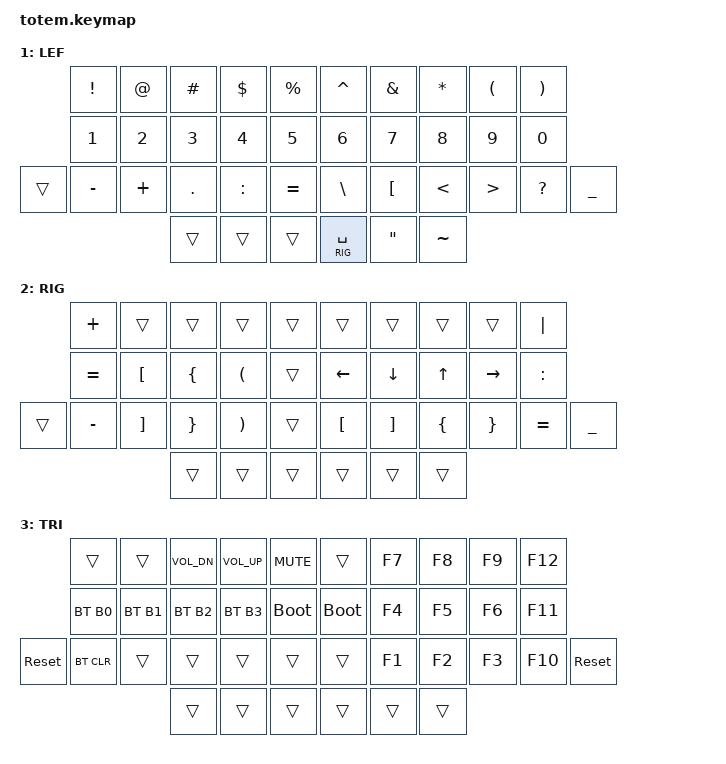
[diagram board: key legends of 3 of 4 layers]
//
//                                                        ▀▀▀▀▀     ▀▀▀▀▀          ▀▀█▀▀
//                                                        ▄▀▀▀▄  ▄  ▄▀▀▀▄  ▄  ▄▀▀▀▄  █  ▄▀▀▀▄
//                                                        █   █  █  █   █  █  █   █  █  █   █
//                                                         ▀▀▀   █   ▀▀▀   █   ▀▀▀   ▀   ▀▀▀
//                                                               █      ▄▄▄█▄▄▄    █   █
//                                                               ▀      █  █  █     █▄█
//                                                             ▀▀▀▀▀    █  █  █      ▀
//                                                                      ▀  ▀  ▀
//
// ▄▄▄▄▄▄▄▄▄▄▄▄▄▄▄▄▄▄▄▄▄▄▄▄▄▄▄▄▄▄▄▄▄▄▄▄▄▄▄▄▄▄▄▄▄▄▄▄▄▄▄▄▄▄▄▄▄▄▄▄▄▄▄▄▄▄▄▄▄▄▄▄▄▄▄▄▄▄▄▄▄▄▄▄▄▄▄▄▄▄▄▄▄▄▄▄▄▄▄▄▄▄▄▄▄▄▄▄▄▄▄▄▄▄▄▄▄▄▄▄▄▄▄▄▄▄▄▄▄▄▄▄▄▄▄▄▄▄▄▄▄▄▄▄▄▄▄▄▄

#include <behaviors.dtsi>
#include <dt-bindings/zmk/bt.h>
#include <dt-bindings/zmk/ext_power.h>
#include <dt-bindings/zmk/keys.h>

// Home row mods macro
#define HRML(k1,k2,k3,k4,k5) &ht LGUI k1  &ht LCTRL k2  &ht LALT k3  &ht LSHFT k4 &ht LG(LC(LA(LSHIFT))) k5
#define HRMR(k1,k2,k3,k4,k5) &ht LG(LC(LA(LSHIFT))) k1 &ht RSHFT k2  &ht RALT k3  &ht RCTRL k4  &ht RGUI k5

// layers
#define BAS 0
#define LEF 1
#define RIG 2
#define TRI 3

// bluetooth
#define B0    BT_SEL 0
#define B1    BT_SEL 1
#define B2    BT_SEL 2
#define B3    BT_SEL 3
#define B4    BT_SEL 4

// media
#define VOL_DN    C_VOL_DN
#define VOL_UP    C_VOL_UP
#define MUTE      C_MUTE

&mt {
    quick-tap-ms = <100>;
    global-quick-tap;
    flavor = "tap-preferred";
    tapping-term-ms = <170>;
};

&lt {
    tapping-term-ms = <240>;
    flavor = "balanced";
    quick-tap-ms = <150>;
};

/ {
    behaviors {
        ht: hold_tap {
            label = "hold_tap";
            compatible = "zmk,behavior-hold-tap";
            #binding-cells = <2>;
            flavor = "tap-preferred";
            tapping-term-ms = <175>;
            quick-tap-ms = <175>;
            require-prior-idle-ms = <125>;
            bindings = <&kp>, <&kp>;
        };
    };

    conditional_layers {
        compatible = "zmk,conditional-layers";
        tri_layer {
            if-layers = <RIG LEF>;
            then-layer = <TRI>;
        };
    };

//             ┏━━━━━━━━━━━┳━━━━━━━━━━━┳━━━━━━━━━━━┳━━━━━━━━━━━┳━━━━━━━━━━━┓   ┏━━━━━━━━━━━┳━━━━━━━━━━━┳━━━━━━━━━━━┳━━━━━━━━━━━┳━━━━━━━━━━━┓
//             ┃     0     ┃     1     ┃     2     ┃     3     ┃     4     ┃   ┃     5     ┃     6     ┃     7     ┃     8     ┃     9     ┃
//             ┣━━━━━━━━━━━╋━━━━━━━━━━━╋━━━━━━━━━━━╋━━━━━━━━━━━╋━━━━━━━━━━━┫   ┣━━━━━━━━━━━╋━━━━━━━━━━━╋━━━━━━━━━━━╋━━━━━━━━━━━╋━━━━━━━━━━━┫
//             ┃    10     ┃    11     ┃    12     ┃    13     ┃    14     ┃   ┃    15     ┃    16     ┃    17     ┃    18     ┃    19     ┃
// ┏━━━━━━━━━━━╋━━━━━━━━━━━╋━━━━━━━━━━━╋━━━━━━━━━━━╋━━━━━━━━━━━╋━━━━━━━━━━━┫   ┣━━━━━━━━━━━╋━━━━━━━━━━━╋━━━━━━━━━━━╋━━━━━━━━━━━╋━━━━━━━━━━━╋━━━━━━━━━━━┓
// ┃    20     ┃    21     ┃    22     ┃    23     ┃    24     ┃    25     ┃   ┃    26     ┃    27     ┃    28     ┃    29     ┃    30     ┃    31     ┃
// ┗━━━━━━━━━━━┻━━━━━━━━━━━┻━━━━━━━━━━━╋━━━━━━━━━━━╋━━━━━━━━━━━╋━━━━━━━━━━━┫   ┣━━━━━━━━━━━╋━━━━━━━━━━━╋━━━━━━━━━━━╋━━━━━━━━━━━┻━━━━━━━━━━━┻━━━━━━━━━━━┛
//                                     ┃    32     ┃    33     ┃    34     ┃   ┃    35     ┃    36     ┃    37     ┃
//                                     ┗━━━━━━━━━━━┻━━━━━━━━━━━┻━━━━━━━━━━━┛   ┗━━━━━━━━━━━┻━━━━━━━━━━━┻━━━━━━━━━━━┛

    combos {
        compatible = "zmk,combos";

        #define COMBO(NAME, BINDINGS, KEYPOS, LAYERS) \
        combo_##NAME { \
            bindings = <BINDINGS>; \
            key-positions = <KEYPOS>; \
            layers = <LAYERS>; \
        };

        // Brackets
        COMBO(left_bracket, &kp LBKT, 1 11, BAS LEF RIG)
        COMBO(left_paren, &kp LPAR, 2 12, BAS LEF RIG)
        COMBO(left_brace, &kp LBRC, 3 13, BAS LEF RIG)
        COMBO(right_bracket, &kp RBKT, 8 18, BAS LEF RIG)
        COMBO(right_paren, &kp RPAR, 7 17, BAS LEF RIG)
        COMBO(right_brace, &kp RBRC, 6 16, BAS LEF RIG)

        // Convenience
        COMBO(enter, &kp ENTER, 16 17 18, BAS LEF RIG)     // jkl

        // +/-
        COMBO(minus, &kp MINUS, 21 34, BAS LEF RIG)        // left wing
        COMBO(plus, &kp PLUS, 22 34, BAS LEF RIG)          // left wing
        // &/?
        COMBO(ampersand, &kp AMPS, 6 34, BAS LEF RIG)      // quick tap layer
        COMBO(layer_qmark, &kp QMARK, 30 34, BAS LEF RIG)     // quick tap layer
        COMBO(shift_qmark, &kp QMARK, 13 30, BAS LEF RIG)     // quick tap shift
    };

    keymap {
        compatible = "zmk,keymap";

// ▄▄▄▄▄▄▄▄▄▄▄▄▄▄▄▄▄▄▄▄▄▄▄▄▄▄▄▄▄▄▄▄▄▄▄▄▄▄▄▄▄▄▄▄▄▄▄▄▄▄▄▄▄▄▄▄▄▄▄▄▄▄▄▄▄▄▄▄▄▄▄▄▄▄▄▄▄▄▄▄▄▄▄▄▄▄▄▄▄▄▄▄▄▄▄▄▄▄▄▄▄▄▄▄▄▄▄▄▄▄▄▄▄▄▄▄▄▄▄▄▄▄▄▄▄▄▄▄▄▄▄▄▄▄▄▄▄▄▄▄▄▄▄▄▄▄▄▄▄

        default_layer {
            label = "BAS";
            bindings = <
//             ┏━━━━━━━━━━━┳━━━━━━━━━━━┳━━━━━━━━━━━┳━━━━━━━━━━━┳━━━━━━━━━━━┓   ┏━━━━━━━━━━━┳━━━━━━━━━━━┳━━━━━━━━━━━┳━━━━━━━━━━━┳━━━━━━━━━━━┓
//             ┃     Q     ┃     W     ┃     E     ┃     R     ┃     T     ┃   ┃     Y     ┃     U     ┃     I     ┃     O     ┃     P     ┃
//             ┣━━━━━━━━━━━╋━━━━━━━━━━━╋━━━━━━━━━━━╋━━━━━━━━━━━╋━━━━━━━━━━━┫   ┣━━━━━━━━━━━╋━━━━━━━━━━━╋━━━━━━━━━━━╋━━━━━━━━━━━╋━━━━━━━━━━━┫
//             ┃     A     ┃     S     ┃     D     ┃     F     ┃     G     ┃   ┃     H     ┃     J     ┃     K     ┃     L     ┃     ;     ┃
// ┏━━━━━━━━━━━╋━━━━━━━━━━━╋━━━━━━━━━━━╋━━━━━━━━━━━╋━━━━━━━━━━━╋━━━━━━━━━━━┫   ┣━━━━━━━━━━━╋━━━━━━━━━━━╋━━━━━━━━━━━╋━━━━━━━━━━━╋━━━━━━━━━━━╋━━━━━━━━━━━┓
// ┃ LCTRL ESC ┃     Z     ┃     X     ┃     C     ┃     V     ┃     B     ┃   ┃     N     ┃     M     ┃     ,     ┃     .     ┃     /     ┃  RSHFT =  ┃
// ┗━━━━━━━━━━━┻━━━━━━━━━━━┻━━━━━━━━━━━╋━━━━━━━━━━━╋━━━━━━━━━━━╋━━━━━━━━━━━┫   ┣━━━━━━━━━━━╋━━━━━━━━━━━╋━━━━━━━━━━━╋━━━━━━━━━━━┻━━━━━━━━━━━┻━━━━━━━━━━━┛
//                                     ┃ LSHFT TAB ┃   BSPC    ┃  LEF SPC  ┃   ┃ RIG ENTER ┃     '     ┃     `     ┃
//                                     ┗━━━━━━━━━━━┻━━━━━━━━━━━┻━━━━━━━━━━━┛   ┗━━━━━━━━━━━┻━━━━━━━━━━━┻━━━━━━━━━━━┛
// ╷           ╷           ╷           ╷           ╷           ╷           ╷   ╷           ╷           ╷           ╷           ╷           ╷           ╷

                 &kp Q       &kp W       &kp E       &kp R       &kp T           &kp Y       &kp U       &kp I       &kp O       &kp P
                HRML(A,          S,          D,          F,          G)         HRMR(H,          J,          K,          L,          SEMI)
    &mt LCTRL ESC &kp Z      &kp X       &kp C       &kp V       &kp B           &kp N       &kp M       &kp COMMA   &kp DOT     &kp FSLH    &mt RSHFT EQUAL
                                       &mt LSHFT TAB &kp BSPC    &lt LEF SPC     &lt RIG RET &kp SQT     &kp GRAVE

            >;
        };

// ▄▄▄▄▄▄▄▄▄▄▄▄▄▄▄▄▄▄▄▄▄▄▄▄▄▄▄▄▄▄▄▄▄▄▄▄▄▄▄▄▄▄▄▄▄▄▄▄▄▄▄▄▄▄▄▄▄▄▄▄▄▄▄▄▄▄▄▄▄▄▄▄▄▄▄▄▄▄▄▄▄▄▄▄▄▄▄▄▄▄▄▄▄▄▄▄▄▄▄▄▄▄▄▄▄▄▄▄▄▄▄▄▄▄▄▄▄▄▄▄▄▄▄▄▄▄▄▄▄▄▄▄▄▄▄▄▄▄▄▄▄▄▄▄▄▄▄▄▄

        left_layer {
            label = "LEF";
            bindings = <
//             ┏━━━━━━━━━━━┳━━━━━━━━━━━┳━━━━━━━━━━━┳━━━━━━━━━━━┳━━━━━━━━━━━┓   ┏━━━━━━━━━━━┳━━━━━━━━━━━┳━━━━━━━━━━━┳━━━━━━━━━━━┳━━━━━━━━━━━┓
//             ┃     !     ┃     @     ┃     #     ┃     $     ┃     %     ┃   ┃     ^     ┃     &     ┃     *     ┃     (     ┃     )     ┃
//             ┣━━━━━━━━━━━╋━━━━━━━━━━━╋━━━━━━━━━━━╋━━━━━━━━━━━╋━━━━━━━━━━━┫   ┣━━━━━━━━━━━╋━━━━━━━━━━━╋━━━━━━━━━━━╋━━━━━━━━━━━╋━━━━━━━━━━━┫
//             ┃     1     ┃     2     ┃     3     ┃     4     ┃     5     ┃   ┃     6     ┃     7     ┃     8     ┃     9     ┃     0     ┃
// ┏━━━━━━━━━━━╋━━━━━━━━━━━╋━━━━━━━━━━━╋━━━━━━━━━━━╋━━━━━━━━━━━╋━━━━━━━━━━━┫   ┣━━━━━━━━━━━╋━━━━━━━━━━━╋━━━━━━━━━━━╋━━━━━━━━━━━╋━━━━━━━━━━━╋━━━━━━━━━━━┓
// ┃    ESC    ┃     -     ┃     +     ┃     .     ┃     :     ┃     =     ┃   ┃     \     ┃     [     ┃     <     ┃     >     ┃     ?     ┃     _     ┃
// ┗━━━━━━━━━━━┻━━━━━━━━━━━┻━━━━━━━━━━━╋━━━━━━━━━━━╋━━━━━━━━━━━╋━━━━━━━━━━━┫   ┣━━━━━━━━━━━╋━━━━━━━━━━━╋━━━━━━━━━━━╋━━━━━━━━━━━┻━━━━━━━━━━━┻━━━━━━━━━━━┛
//                                     ┃ LSHFT TAB ┃   BSPC    ┃  LEF SPC  ┃   ┃  RIG SPC  ┃     "     ┃     ~     ┃
//                                     ┗━━━━━━━━━━━┻━━━━━━━━━━━┻━━━━━━━━━━━┛   ┗━━━━━━━━━━━┻━━━━━━━━━━━┻━━━━━━━━━━━┛
// ╷           ╷           ╷           ╷           ╷           ╷           ╷   ╷           ╷           ╷           ╷           ╷           ╷           ╷

                 &kp EXCL    &kp AT      &kp HASH    &kp DLLR    &kp PRCNT       &kp CARET   &kp AMPS    &kp STAR    &kp LPAR   &kp RPAR
                 &kp N1      &kp N2      &kp N3      &kp N4      &kp N5          &kp N6      &kp N7      &kp N8      &kp N9     &kp N0
    &trans       &kp MINUS   &kp PLUS    &kp PERIOD  &kp COLON   &kp EQUAL       &kp BSLH    &kp LBKT    &kp LT      &kp GT     &kp QMARK    &kp UNDER
                                         &trans      &trans      &trans          &lt RIG SPC &kp DQT     &kp TILDE

            >;
        };

// ▄▄▄▄▄▄▄▄▄▄▄▄▄▄▄▄▄▄▄▄▄▄▄▄▄▄▄▄▄▄▄▄▄▄▄▄▄▄▄▄▄▄▄▄▄▄▄▄▄▄▄▄▄▄▄▄▄▄▄▄▄▄▄▄▄▄▄▄▄▄▄▄▄▄▄▄▄▄▄▄▄▄▄▄▄▄▄▄▄▄▄▄▄▄▄▄▄▄▄▄▄▄▄▄▄▄▄▄▄▄▄▄▄▄▄▄▄▄▄▄▄▄▄▄▄▄▄▄▄▄▄▄▄▄▄▄▄▄▄▄▄▄▄▄▄▄▄▄▄

        right_layer {
            label = "RIG";
            bindings = <
//             ┏━━━━━━━━━━━┳━━━━━━━━━━━┳━━━━━━━━━━━┳━━━━━━━━━━━┳━━━━━━━━━━━┓   ┏━━━━━━━━━━━┳━━━━━━━━━━━┳━━━━━━━━━━━┳━━━━━━━━━━━┳━━━━━━━━━━━┓
//             ┃     +     ┃           ┃           ┃           ┃           ┃   ┃           ┃           ┃           ┃           ┃     |     ┃
//             ┣━━━━━━━━━━━╋━━━━━━━━━━━╋━━━━━━━━━━━╋━━━━━━━━━━━╋━━━━━━━━━━━┫   ┣━━━━━━━━━━━╋━━━━━━━━━━━╋━━━━━━━━━━━╋━━━━━━━━━━━╋━━━━━━━━━━━┫
//             ┃     =     ┃     [     ┃     {     ┃     (     ┃           ┃   ┃   LEFT    ┃   DOWN    ┃    UP     ┃   RIGHT   ┃     :     ┃
// ┏━━━━━━━━━━━╋━━━━━━━━━━━╋━━━━━━━━━━━╋━━━━━━━━━━━╋━━━━━━━━━━━╋━━━━━━━━━━━┫   ┣━━━━━━━━━━━╋━━━━━━━━━━━╋━━━━━━━━━━━╋━━━━━━━━━━━╋━━━━━━━━━━━╋━━━━━━━━━━━┓
// ┃    ESC    ┃     -     ┃     ]     ┃     }     ┃     )     ┃           ┃   ┃     [     ┃     ]     ┃     {     ┃     }     ┃     =     ┃     _     ┃
// ┗━━━━━━━━━━━┻━━━━━━━━━━━┻━━━━━━━━━━━╋━━━━━━━━━━━╋━━━━━━━━━━━╋━━━━━━━━━━━┫   ┣━━━━━━━━━━━╋━━━━━━━━━━━╋━━━━━━━━━━━╋━━━━━━━━━━━┻━━━━━━━━━━━┻━━━━━━━━━━━┛
//                                     ┃ LSHFT TAB ┃   BSPC    ┃  LEF SPC  ┃   ┃ RIG ENTER ┃     '     ┃     `     ┃
//                                     ┗━━━━━━━━━━━┻━━━━━━━━━━━┻━━━━━━━━━━━┛   ┗━━━━━━━━━━━┻━━━━━━━━━━━┻━━━━━━━━━━━┛
// ╷           ╷           ╷           ╷           ╷           ╷           ╷   ╷           ╷           ╷           ╷           ╷           ╷           ╷

                &kp PLUS    &trans      &trans      &trans       &trans         &trans      &trans      &trans      &trans      &kp PIPE
                &kp EQUAL   &kp LBKT    &kp LBRC    &kp LPAR     &trans         &kp LEFT    &kp DOWN    &kp UP      &kp RIGHT   &kp COLON
    &trans      &kp MINUS   &kp RBKT    &kp RBRC    &kp RPAR     &trans         &kp LBKT    &kp RBKT    &kp LBRC    &kp RBRC    &kp EQUAL    &kp UNDER
                                        &trans      &trans       &trans         &trans      &trans      &trans

            >;
        };

// ▄▄▄▄▄▄▄▄▄▄▄▄▄▄▄▄▄▄▄▄▄▄▄▄▄▄▄▄▄▄▄▄▄▄▄▄▄▄▄▄▄▄▄▄▄▄▄▄▄▄▄▄▄▄▄▄▄▄▄▄▄▄▄▄▄▄▄▄▄▄▄▄▄▄▄▄▄▄▄▄▄▄▄▄▄▄▄▄▄▄▄▄▄▄▄▄▄▄▄▄▄▄▄▄▄▄▄▄▄▄▄▄▄▄▄▄▄▄▄▄▄▄▄▄▄▄▄▄▄▄▄▄▄▄▄▄▄▄▄▄▄▄▄▄▄▄▄▄▄

        tri_layer {
            label = "TRI";
            bindings = <
//             ┏━━━━━━━━━━━┳━━━━━━━━━━━┳━━━━━━━━━━━┳━━━━━━━━━━━┳━━━━━━━━━━━┓   ┏━━━━━━━━━━━┳━━━━━━━━━━━┳━━━━━━━━━━━┳━━━━━━━━━━━┳━━━━━━━━━━━┓
//             ┃           ┃           ┃   VOL-    ┃   VOL+    ┃   MUTE    ┃   ┃           ┃    F7     ┃    F8     ┃    F9     ┃    F12    ┃
//             ┣━━━━━━━━━━━╋━━━━━━━━━━━╋━━━━━━━━━━━╋━━━━━━━━━━━╋━━━━━━━━━━━┫   ┣━━━━━━━━━━━╋━━━━━━━━━━━╋━━━━━━━━━━━╋━━━━━━━━━━━╋━━━━━━━━━━━┫
//             ┃ PROFILE 0 ┃ PROFILE 1 ┃ PROFILE 2 ┃ PROFILE 3 ┃ BOOTLOAD  ┃   ┃ BOOTLOAD  ┃    F4     ┃    F5     ┃    F6     ┃    F11    ┃
// ┏━━━━━━━━━━━╋━━━━━━━━━━━╋━━━━━━━━━━━╋━━━━━━━━━━━╋━━━━━━━━━━━╋━━━━━━━━━━━┫   ┣━━━━━━━━━━━╋━━━━━━━━━━━╋━━━━━━━━━━━╋━━━━━━━━━━━╋━━━━━━━━━━━╋━━━━━━━━━━━┓
// ┃   RESET   ┃ BT CLEAR  ┃           ┃           ┃           ┃           ┃   ┃           ┃    F1     ┃    F2     ┃    F3     ┃    F10    ┃   RESET   ┃
// ┗━━━━━━━━━━━┻━━━━━━━━━━━┻━━━━━━━━━━━╋━━━━━━━━━━━╋━━━━━━━━━━━╋━━━━━━━━━━━┫   ┣━━━━━━━━━━━╋━━━━━━━━━━━╋━━━━━━━━━━━╋━━━━━━━━━━━┻━━━━━━━━━━━┻━━━━━━━━━━━┛
//                                     ┃           ┃           ┃           ┃   ┃           ┃           ┃           ┃
//                                     ┗━━━━━━━━━━━┻━━━━━━━━━━━┻━━━━━━━━━━━┛   ┗━━━━━━━━━━━┻━━━━━━━━━━━┻━━━━━━━━━━━┛
// ╷           ╷           ╷           ╷           ╷           ╷           ╷   ╷           ╷           ╷           ╷           ╷           ╷           ╷

                &trans       &trans     &kp VOL_DN  &kp VOL_UP  &kp MUTE        &trans      &kp F7      &kp F8      &kp F9      &kp F12
                &bt B0       &bt B1     &bt B2      &bt B3      &bootloader     &bootloader &kp F4      &kp F5      &kp F6      &kp F11
    &sys_reset  &bt BT_CLR   &trans     &trans      &trans      &trans          &trans      &kp F1      &kp F2      &kp F3      &kp F10      &sys_reset
                                        &trans      &trans      &trans          &trans      &trans      &trans

            >;
        };
    };
};
